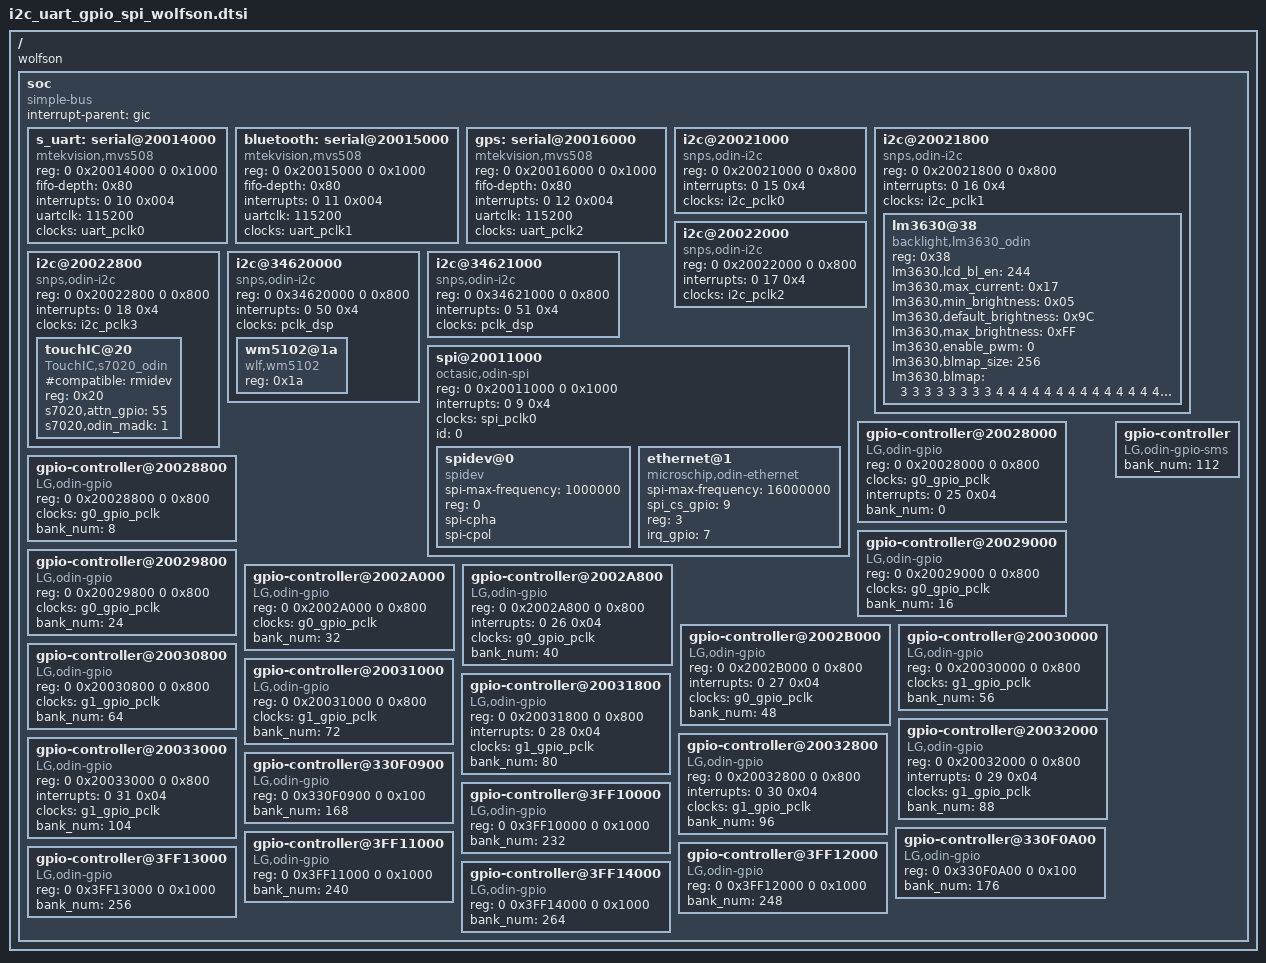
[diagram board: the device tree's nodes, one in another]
/*
 * LG Electronics I2C for ODIN/Woden
 */

/ {
	wolfson;
	
	soc{
		compatible = "simple-bus";
  		interrupt-parent = <&gic>;
		#address-cells = <2>;
		#size-cells = <2>;
		ranges;

		s_uart: serial@20014000 {
			compatible = "mtekvision,mvs508";
			reg = <0 0x20014000 0 0x1000>;
			fifo-depth = <0x80>;
			interrupts = <0 10 0x004>;
			uartclk = <115200>;
			clocks = <&uart_pclk0>;
		};

	   bluetooth: serial@20015000 {
			compatible = "mtekvision,mvs508";
			reg = <0 0x20015000 0 0x1000>;
			fifo-depth = <0x80>;
			interrupts = <0 11 0x004>;
			uartclk = <115200>;
			clocks = <&uart_pclk1>;
		};

	   gps: serial@20016000 {
			compatible = "mtekvision,mvs508";
			reg = <0 0x20016000 0 0x1000>;
			fifo-depth = <0x80>;
			interrupts = <0 12 0x004>;
			uartclk = <115200>;
			clocks = <&uart_pclk2>;
		};

/* i2c start */

		i2c@20021000 {
			compatible = "snps,odin-i2c";
			reg = <0 0x20021000 0 0x800>;
			interrupts = <0 15 0x4>;
			clocks = <&i2c_pclk0>;
		};

		i2c@20021800 {
			compatible = "snps,odin-i2c";
			reg = <0 0x20021800 0 0x800>;
			interrupts = <0 16 0x4>;
			clocks = <&i2c_pclk1>;
			#address-cells = <1>;
			#size-cells = <0>;

			lm3630@38{
				compatible = "backlight,lm3630_odin";
				status = "ok";
				reg = <0x38>;
				lm3630,lcd_bl_en = <244>;	/* ICS GPIO 12 default for madk 1v1 */
				lm3630,max_current = <0x17>;
				lm3630,min_brightness = <0x05>;
				lm3630,default_brightness = <0x9C>;
				lm3630,max_brightness = <0xFF>;
				lm3630,enable_pwm = <0>;
				lm3630,blmap_size = <256>;
				lm3630,blmap = <
					3 3 3 3 3 3 3 3 4 4 4 4 4 4 4
					4 4 4 4 4 4 4 5 5 5 5 5 5 5 5
					5 5 5 5 5 6 6 6 6 6 6 6 6 7 7
					7 8 8 8 9 9 9 9 9 10 10 10 11 11 11
					12 12 12 12 13 13 13 13 14 14 15 15 15 16 16
					17 17 17 18 18 18 19 19 20 21 22 22 23 24 24
					25 25 26 26 27 28 28 29 29 30 30 31 31 32 32
					33 34 35 35 36 36 37 38 39 39 40 41 41 42 43
					44 45 45 46 47 48 49 50 51 52 53 54 55 56 57
					58 59 60 61 62 63 64 65 66 67 68 69 70 71 72
					73 74 75 76 76 77 78 80 81 82 83 85 86 87 88
					89 90 91 93 95 96 97 99 100 102 103 104 106 107 108
					109 110 112 114 115 117 119 121 123 125 127 128 129 130 132
					133 135 136 138 139 140 142 144 146 148 150 151 153 154 156
					157 158 159 161 163 164 165 167 168 170 173 175 177 180 184
					186 188 191 194 197 199 201 203 205 207 209 211 213 215 217
					219 221 223 225 227 228 230 232 235 238 240 243 246 249 252
					255>;
				};
		};

		i2c@20022000 {
			compatible = "snps,odin-i2c";
			reg = <0 0x20022000 0 0x800>;
			interrupts = <0 17 0x4>;
			clocks = <&i2c_pclk2>;
		};

		i2c@20022800 {
			compatible = "snps,odin-i2c";
			reg = <0 0x20022800 0 0x800>;
			interrupts = <0 18 0x4>;
			clocks = <&i2c_pclk3>;
			#address-cells = <1>;
			#size-cells = <0>;

			touchIC@20{
				#compatible = "rmidev";
				compatible = "TouchIC,s7020_odin";
				reg = <0x20>;
				s7020,attn_gpio = <55>;
				s7020,odin_madk = <1>;
			};
		};

		i2c@34620000 {
			compatible = "snps,odin-i2c";
			reg = <0 0x34620000 0 0x800>;
			interrupts = <0 50 0x4>;
			clocks = <&pclk_dsp>;
			#address-cells = <1>;
			#size-cells = <0>;

			wm5102@1a{
				compatible = "wlf,wm5102";
				reg = <0x1a>;
			};
		};

		i2c@34621000 {
			compatible = "snps,odin-i2c";
			reg = <0 0x34621000 0 0x800>;
			interrupts = <0 51 0x4>;
			clocks = <&pclk_dsp>;
		};
/* i2c end */

/* spi start */
		spi@20011000 {
			compatible = "octasic,odin-spi";
			reg = <0 0x20011000 0 0x1000>;
			interrupts = <0 9 0x4>;
			clocks = <&spi_pclk0>;
			id = <0>;
			#address-cells = <1>;
			#size-cells = <0>;

			spidev@0{
				compatible = "spidev";
				spi-max-frequency = <1000000>;
				reg = <0>;
				spi-cpha;
				spi-cpol;
			};

			ethernet@1{
				compatible = "microschip,odin-ethernet";
				spi-max-frequency = <16000000>;
				spi_cs_gpio = <9>;
				reg = <3>;
				irq_gpio = <7>;
			};
		};

/* spi end */
/*---- peri gpio controller ----*/
/* G0_GPIO0~6 */
		gpio-controller@20028000 {
			compatible = "LG,odin-gpio";
			reg = <0 0x20028000 0 0x800>;
			clocks = <&g0_gpio_pclk>;
			interrupts = <0 25 0x04>;
			bank_num = <0>;
		};
		gpio-controller@20028800 {
			compatible = "LG,odin-gpio";
			reg = <0 0x20028800 0 0x800>;
			clocks = <&g0_gpio_pclk>;
			bank_num = <8>;
		};
		gpio-controller@20029000 {
			compatible = "LG,odin-gpio";
			reg = <0 0x20029000 0 0x800>;
			clocks = <&g0_gpio_pclk>;
			bank_num = <16>;
		};
		gpio-controller@20029800 {
			compatible = "LG,odin-gpio";
			reg = <0 0x20029800 0 0x800>;
			clocks = <&g0_gpio_pclk>;
			bank_num = <24>;
		};
		gpio-controller@2002A000 {
			compatible = "LG,odin-gpio";
			reg = <0 0x2002A000 0 0x800>;
			clocks = <&g0_gpio_pclk>;
			bank_num = <32>;
		};
		gpio-controller@2002A800 {
			compatible = "LG,odin-gpio";
			reg = <0 0x2002A800 0 0x800>;
			interrupts = <0 26 0x04>;
			clocks = <&g0_gpio_pclk>;
			bank_num = <40>;
		};
		gpio-controller@2002B000 {
			compatible = "LG,odin-gpio";
			reg = <0 0x2002B000 0 0x800>;
			interrupts = <0 27 0x04>;
			clocks = <&g0_gpio_pclk>;
			bank_num = <48>;
		};
	/* G1_GPIO0~6 */
		gpio-controller@20030000 {
			compatible = "LG,odin-gpio";
			reg = <0 0x20030000 0 0x800>;
			clocks = <&g1_gpio_pclk>;
			bank_num = <56>;
		};
		gpio-controller@20030800 {
			compatible = "LG,odin-gpio";
			reg = <0 0x20030800 0 0x800>;
			clocks = <&g1_gpio_pclk>;
			bank_num = <64>;
		};
		gpio-controller@20031000 {
			compatible = "LG,odin-gpio";
			reg = <0 0x20031000 0 0x800>;
			clocks = <&g1_gpio_pclk>;
			bank_num = <72>;
		};
		gpio-controller@20031800 {
			compatible = "LG,odin-gpio";
			reg = <0 0x20031800 0 0x800>;
			interrupts = <0 28 0x04>;
			clocks = <&g1_gpio_pclk>;
			bank_num = <80>;
		};
		gpio-controller@20032000 {
			compatible = "LG,odin-gpio";
			reg = <0 0x20032000 0 0x800>;
			interrupts = <0 29 0x04>;
			clocks = <&g1_gpio_pclk>;
			bank_num = <88>;
		};
		gpio-controller@20032800 {
			compatible = "LG,odin-gpio";
			reg = <0 0x20032800 0 0x800>;
			interrupts = <0 30 0x04>;
			clocks = <&g1_gpio_pclk>;
			bank_num = <96>;
		};
		gpio-controller@20033000 {
			compatible = "LG,odin-gpio";
			reg = <0 0x20033000 0 0x800>;
			interrupts = <0 31 0x04>;
			clocks = <&g1_gpio_pclk>;
			bank_num = <104>;
		};
	/*---- peri gpio controller end ----*/

	/*---- sms gpio controller ----*/
		gpio-controller {
			compatible = "LG,odin-gpio-sms";
			bank_num = <112>;
		};
	/*---- sms gpio controller end ----*/
	/*---- css gpio controller ----*/
		gpio-controller@330F0900 {
			compatible = "LG,odin-gpio";
			reg = <0 0x330F0900 0 0x100>;
			bank_num = <168>;
		};
		gpio-controller@330F0A00 {
			compatible = "LG,odin-gpio";
			reg = <0 0x330F0A00 0 0x100>;
			bank_num = <176>;
		};
/*---- css gpio controller end ----*/

	/*---- ics gpio controller start ----*/
		gpio-controller@3FF10000 {
			compatible = "LG,odin-gpio";
			reg = <0 0x3FF10000 0 0x1000>;
			bank_num = <232>;
		};
		gpio-controller@3FF11000 {
			compatible = "LG,odin-gpio";
			reg = <0 0x3FF11000 0 0x1000>;
			bank_num = <240>;
		};
		gpio-controller@3FF12000 {
			compatible = "LG,odin-gpio";
			reg = <0 0x3FF12000 0 0x1000>;
			bank_num = <248>;
		};
		gpio-controller@3FF13000 {
			compatible = "LG,odin-gpio";
			reg = <0 0x3FF13000 0 0x1000>;
			bank_num = <256>;
		};
		gpio-controller@3FF14000 {
			compatible = "LG,odin-gpio";
			reg = <0 0x3FF14000 0 0x1000>;
			bank_num = <264>;
		};
	/*---- ics gpio controller end ----*/
	};
};
